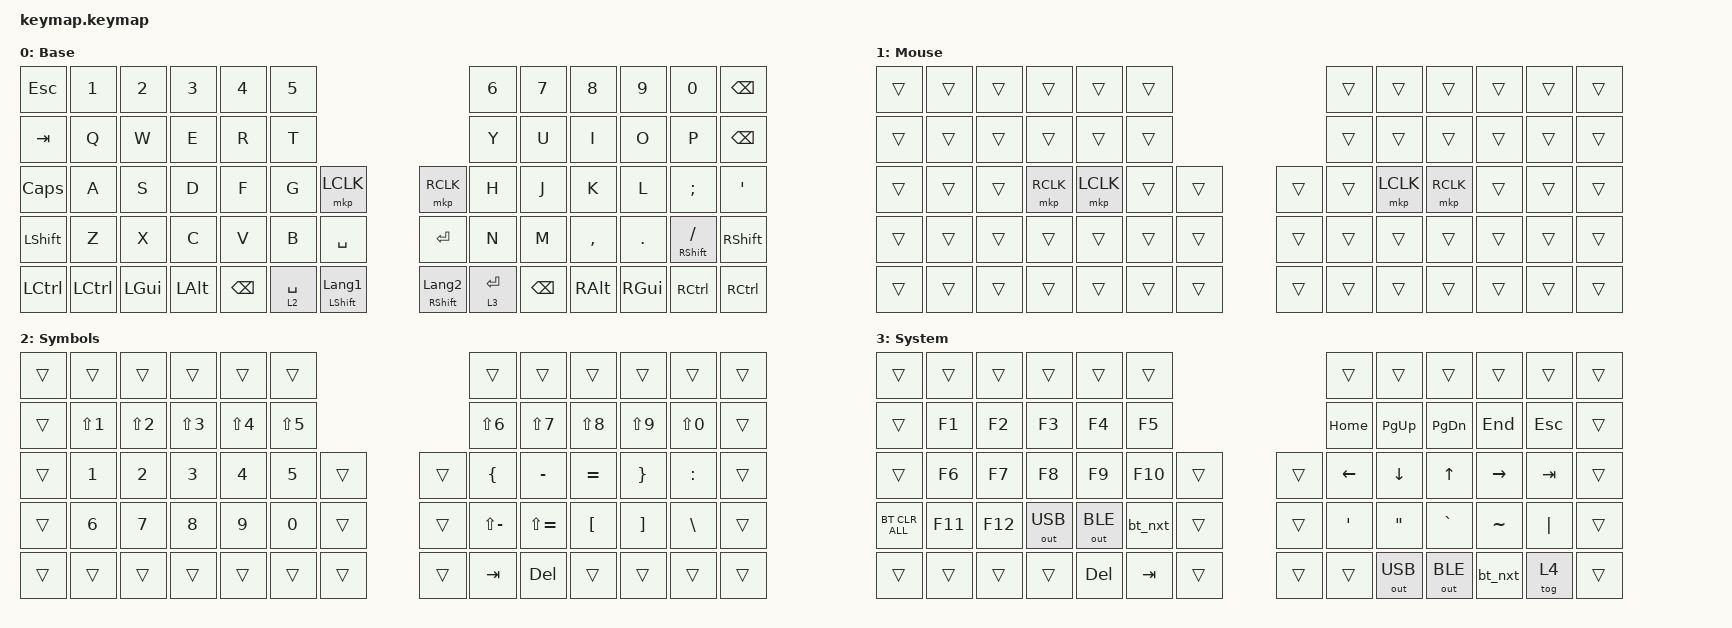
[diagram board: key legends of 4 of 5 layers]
#include <behaviors.dtsi>
#include <dt-bindings/zmk/bt.h>
#include <dt-bindings/zmk/keys.h>
#include <dt-bindings/zmk/outputs.h>
#include <dt-bindings/zmk/pointing.h>
#include <behaviors/runtime_macro.dtsi>

#define TSUKI_TRANS_12 &trans &trans &trans &trans &trans &trans &trans &trans &trans &trans &trans &trans
#define TSUKI_TRANS_14 TSUKI_TRANS_12 &trans &trans
#define TSUKI_TRANS_LAYER TSUKI_TRANS_12 TSUKI_TRANS_12 TSUKI_TRANS_14 TSUKI_TRANS_14 TSUKI_TRANS_14
#define TSUKI_RESERVE_LAYER(node_name, layer_name) \
    node_name {                                      \
        status = "disabled";                        \
        display-name = layer_name;                   \
        bindings = <TSUKI_TRANS_LAYER>;              \
    };

&mt {
    flavor = "balanced";
    tapping-term-ms = <230>;
    quick-tap-ms = <150>;
    require-prior-idle-ms = <125>;
};

&lt {
    flavor = "tap-preferred";
    tapping-term-ms = <230>;
    quick-tap-ms = <150>;
    require-prior-idle-ms = <125>;
};

/ {
    behaviors {
        amka: amka {
            compatible = "zmk,behavior-input-processor-temp-layer-keep-active";
            #binding-cells = <0>;
            processor-name = "mouse";
            display-name = "Keep Auto-Mouse Layer";
        };

        mt_safe: mod_tap_safe {
            compatible = "zmk,behavior-hold-tap";
            #binding-cells = <2>;
            flavor = "tap-preferred";
            tapping-term-ms = <230>;
            quick-tap-ms = <150>;
            require-prior-idle-ms = <125>;
            bindings = <&kp>, <&kp>;
            display-name = "Mod-Tap Safe";
        };
    };

    macros {
        bt_nxt: bt_nxt {
            compatible = "zmk,behavior-macro";
            #binding-cells = <0>;
            wait-ms = <50>;
            bindings = <&out OUT_BLE &bt BT_NXT &bt BT_DISC 0 &bt BT_DISC 1 &bt BT_DISC 2 &bt BT_DISC 3 &bt BT_DISC 4>;
            display-name = "BLE Next";
        };
    };

    runtime_combo_defaults {
        compatible = "cormoran,runtime-combo-defaults";

        bt_clear {
            slot = <0>;
            bindings = <&bt BT_CLR_ALL>;
            key-positions = <32 33>;
            layers = <3>;
            display-name = "Clear All BLE";
        };
    };

    keymap {
        compatible = "zmk,keymap";

        layer_0 {
            display-name = "Base";
            bindings = <
&kp ESC    &kp N1     &kp N2    &kp N3    &kp N4    &kp N5                                                         &kp N6       &kp N7    &kp N8     &kp N9    &kp N0                &kp BSPC
&kp TAB    &kp Q      &kp W     &kp E     &kp R     &kp T                                                          &kp Y        &kp U     &kp I      &kp O     &kp P                 &kp BSPC
&kp CAPS   &kp A      &kp S     &kp D     &kp F     &kp G        &mkp LCLK                  &mkp RCLK              &kp H        &kp J     &kp K      &kp L     &kp SEMI              &kp SQT
&kp LSHFT  &kp Z      &kp X     &kp C     &kp V     &kp B        &kp SPACE                  &kp RET                &kp N        &kp M     &kp COMMA  &kp DOT   &mt RIGHT_SHIFT FSLH  &kp RSHFT
&kp LCTRL  &kp LCTRL  &kp LGUI  &kp LALT  &kp BSPC  &lt 2 SPACE  &mt_safe LEFT_SHIFT LANGUAGE_1  &mt_safe RSHIFT LANGUAGE_2  &lt 3 ENTER  &kp BSPC  &kp RALT   &kp RGUI  &kp RCTRL             &kp RCTRL
            >;
        };

        layer_1 {
            display-name = "Mouse";
            bindings = <
&trans  &trans  &trans  &trans     &trans     &trans                  &trans  &trans     &trans     &trans  &trans  &trans
&trans  &trans  &trans  &trans     &trans     &trans                  &trans  &trans     &trans     &trans  &trans  &trans
&trans  &trans  &trans  &mkp RCLK  &mkp LCLK  &trans  &trans  &trans  &trans  &mkp LCLK  &mkp RCLK  &trans  &trans  &trans
&trans  &trans  &trans  &trans     &trans     &trans  &trans  &trans  &trans  &trans     &trans     &trans  &trans  &trans
&trans  &trans  &trans  &trans     &trans     &trans  &trans  &trans  &trans  &trans     &trans     &trans  &trans  &trans
            >;
        };

        layer_2 {
            display-name = "Symbols";
            bindings = <
&trans  &trans            &trans            &trans      &trans      &trans                      &trans          &trans         &trans            &trans             &trans         &trans
&trans  &kp LS(NUMBER_1)  &kp LS(NUMBER_2)  &kp LS(N3)  &kp LS(N4)  &kp LS(N5)                  &kp LS(N6)      &kp LS(N7)     &kp LS(N8)        &kp LS(N9)         &kp LS(N0)     &trans
&trans  &kp N1            &kp N2            &kp N3      &kp N4      &kp N5      &trans  &trans  &kp LEFT_BRACE  &kp MINUS      &kp EQUAL         &kp RIGHT_BRACE    &kp COLON      &trans
&trans  &kp N6            &kp N7            &kp N8      &kp N9      &kp N0      &trans  &trans  &kp LS(MINUS)   &kp LS(EQUAL)  &kp LEFT_BRACKET  &kp RIGHT_BRACKET  &kp BACKSLASH  &trans
&trans  &trans            &trans            &trans      &trans      &trans      &trans  &trans  &kp TAB         &kp DEL        &trans            &trans             &trans         &trans
            >;
        };

        layer_3 {
            display-name = "System";
            bindings = <
&trans  &trans   &trans   &trans        &trans        &trans                      &trans            &trans     &trans         &trans     &trans      &trans
&trans  &kp F1   &kp F2   &kp F3        &kp F4        &kp F5                      &kp HOME          &kp PG_UP  &kp PAGE_DOWN  &kp END    &kp ESCAPE  &trans
&trans  &kp F6   &kp F7   &kp F8        &kp F9        &kp F10     &trans  &trans  &kp LEFT          &kp DOWN   &kp UP_ARROW   &kp RIGHT  &kp TAB     &trans
&bt BT_CLR_ALL  &kp F11  &kp F12  &out OUT_USB  &out OUT_BLE  &bt_nxt     &trans  &trans  &kp SINGLE_QUOTE  &kp DQT    &kp GRAVE      &kp TILDE  &kp PIPE    &trans
&trans  &trans   &trans   &trans        &kp DELETE    &kp TAB     &trans  &trans  &trans            &out OUT_USB  &out OUT_BLE  &bt_nxt  &tog 4  &trans
            >;
        };

        layer_4 {
            display-name = "Scroll";
            bindings = <TSUKI_TRANS_LAYER>;
        };

        // DYA currently enables its add button only when free slots outnumber active layers.
        TSUKI_RESERVE_LAYER(reserve_layer_5, "Layer 5")
        TSUKI_RESERVE_LAYER(reserve_layer_6, "Layer 6")
        TSUKI_RESERVE_LAYER(reserve_layer_7, "Layer 7")
        TSUKI_RESERVE_LAYER(reserve_layer_8, "Layer 8")
        TSUKI_RESERVE_LAYER(reserve_layer_9, "Layer 9")
        TSUKI_RESERVE_LAYER(reserve_layer_10, "Layer 10")
        TSUKI_RESERVE_LAYER(reserve_layer_11, "Layer 11")
        TSUKI_RESERVE_LAYER(reserve_layer_12, "Layer 12")
        TSUKI_RESERVE_LAYER(reserve_layer_13, "Layer 13")
        TSUKI_RESERVE_LAYER(reserve_layer_14, "Layer 14")
    };
};
